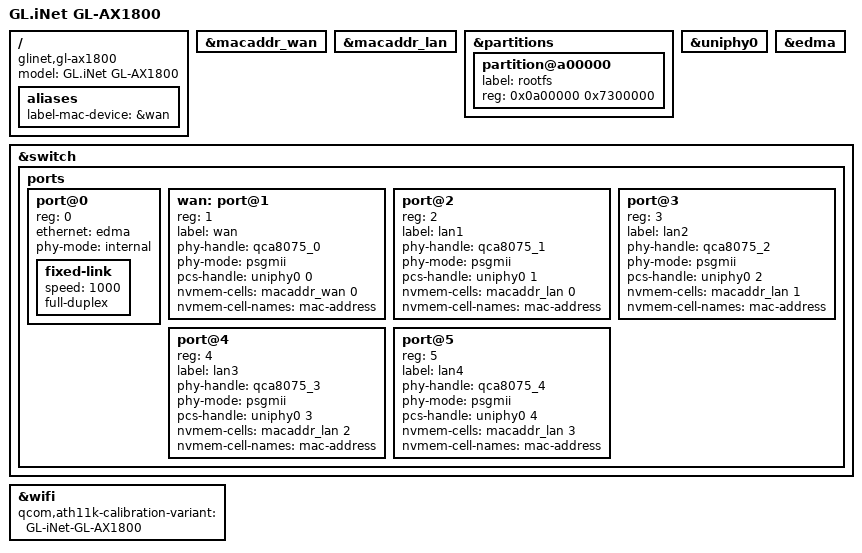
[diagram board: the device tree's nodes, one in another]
// SPDX-License-Identifier: GPL-2.0-or-later OR MIT

/dts-v1/;

#include "ipq6000-glinet-cleanup.dtsi"

/ {
	model = "GL.iNet GL-AX1800";
	compatible = "glinet,gl-ax1800", "qcom,ipq6018";

	aliases {
		label-mac-device = &wan;
	};
};

&macaddr_wan {
	#nvmem-cell-cells = <1>;
};

&macaddr_lan {
	#nvmem-cell-cells = <1>;
};

&partitions {
	partition@a00000 {
		label = "rootfs";
		reg = <0x0a00000 0x7300000>;
	};
};

&uniphy0 {
	status = "okay";
};

&edma {
	status = "okay";
};

&switch {
	status = "okay";

	ports {
		#address-cells = <1>;
		#size-cells = <0>;

		port@0 {
			reg = <0>;
			ethernet = <&edma>;
			phy-mode = "internal";

			fixed-link {
				speed = <1000>;
				full-duplex;
			};
		};

		wan: port@1 {
			reg = <1>;
			label = "wan";
			phy-handle = <&qca8075_0>;
			phy-mode = "psgmii";
			pcs-handle = <&uniphy0 0>;
			nvmem-cells = <&macaddr_wan 0>;
			nvmem-cell-names = "mac-address";
		};

		port@2 {
			reg = <2>;
			label = "lan1";
			phy-handle = <&qca8075_1>;
			phy-mode = "psgmii";
			pcs-handle = <&uniphy0 1>;
			nvmem-cells = <&macaddr_lan 0>;
			nvmem-cell-names = "mac-address";
		};

		port@3 {
			reg = <3>;
			label = "lan2";
			phy-handle = <&qca8075_2>;
			phy-mode = "psgmii";
			pcs-handle = <&uniphy0 2>;
			nvmem-cells = <&macaddr_lan 1>;
			nvmem-cell-names = "mac-address";
		};

		port@4 {
			reg = <4>;
			label = "lan3";
			phy-handle = <&qca8075_3>;
			phy-mode = "psgmii";
			pcs-handle = <&uniphy0 3>;
			nvmem-cells = <&macaddr_lan 2>;
			nvmem-cell-names = "mac-address";
		};

		port@5 {
			reg = <5>;
			label = "lan4";
			phy-handle = <&qca8075_4>;
			phy-mode = "psgmii";
			pcs-handle = <&uniphy0 4>;
			nvmem-cells = <&macaddr_lan 3>;
			nvmem-cell-names = "mac-address";
		};
	};
};

&wifi {
	qcom,ath11k-calibration-variant = "GL-iNet-GL-AX1800";
};
